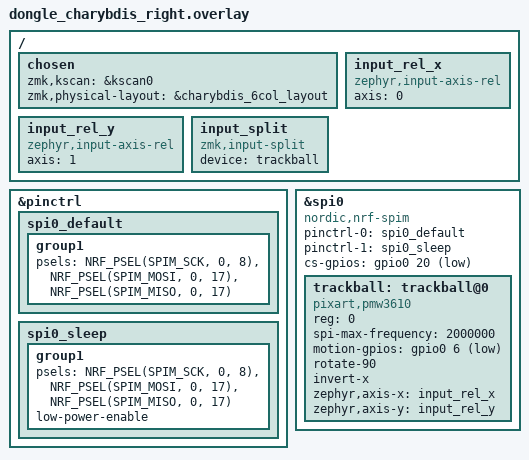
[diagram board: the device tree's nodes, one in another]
/* boards/shields/charybdis/dongle_charybdis_right.overlay */

#include "charybdis.dtsi"

/ {
    chosen {
        zmk,kscan = &kscan0;
        zmk,physical-layout = &charybdis_6col_layout;
    };

    /* [Dongle 모드용] 트랙볼 신호를 중앙(동글)으로 전송 */
    /* zephyr 축 설정은 필요하지만, 처리는 input_split이 담당 */
    input_rel_x: input_rel_x {
        #input-axis-cells = <0>;
        compatible = "zephyr,input-axis-rel";
        axis = <0>;
    };

    input_rel_y: input_rel_y {
        #input-axis-cells = <0>;
        compatible = "zephyr,input-axis-rel";
        axis = <1>;
    };

    /* 여기가 다릅니다! Listener 대신 Split 사용 */
    input_split: input_split {
        compatible = "zmk,input-split";
        device = <&trackball>;
    };
};

/* 핀 설정은 위와 동일 (복붙) */
&pinctrl {
    spi0_default: spi0_default {
        group1 {
            psels = <NRF_PSEL(SPIM_SCK, 0, 8)>,
                    <NRF_PSEL(SPIM_MOSI, 0, 17)>,
                    <NRF_PSEL(SPIM_MISO, 0, 17)>;
        };
    };
    spi0_sleep: spi0_sleep {
        group1 {
            psels = <NRF_PSEL(SPIM_SCK, 0, 8)>,
                    <NRF_PSEL(SPIM_MOSI, 0, 17)>,
                    <NRF_PSEL(SPIM_MISO, 0, 17)>;
            low-power-enable;
        };
    };
};

&spi0 {
    status = "okay";
    compatible = "nordic,nrf-spim";
    pinctrl-0 = <&spi0_default>;
    pinctrl-1 = <&spi0_sleep>;
    pinctrl-names = "default", "sleep";
    cs-gpios = <&gpio0 20 GPIO_ACTIVE_LOW>;

    trackball: trackball@0 {
        status = "okay";
        compatible = "pixart,pmw3610";
        reg = <0>;
        spi-max-frequency = <2000000>;
        motion-gpios = <&gpio0 6 (GPIO_ACTIVE_LOW | GPIO_PULL_UP)>;
        rotate-90;
        invert-x;
        zephyr,axis-x = <&input_rel_x>;
        zephyr,axis-y = <&input_rel_y>;
    };
};
